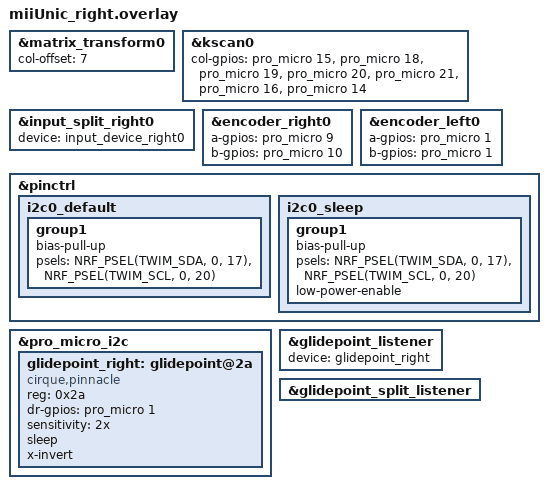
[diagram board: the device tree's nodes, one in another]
#include "miiUnic.dtsi"

&matrix_transform0 {
    col-offset = <7>;
};

&kscan0 {
    col-gpios
        = <&pro_micro 15 GPIO_ACTIVE_HIGH>
        , <&pro_micro 18 GPIO_ACTIVE_HIGH>
        , <&pro_micro 19 GPIO_ACTIVE_HIGH>
        , <&pro_micro 20 GPIO_ACTIVE_HIGH>
        , <&pro_micro 21 GPIO_ACTIVE_HIGH>
        , <&pro_micro 16 GPIO_ACTIVE_HIGH>
        , <&pro_micro 14 GPIO_ACTIVE_HIGH>
        ;
};
// == Input devices ==
// Enabling input-split for its own input devices
// Adding input devices and assigning them to input-split
&input_split_right0 {
    status = "okay";
    device = <&input_device_right0>;
};

&encoder_right0 {
    a-gpios = <&pro_micro 9 (GPIO_ACTIVE_HIGH | GPIO_PULL_UP)>;
    b-gpios = <&pro_micro 10 (GPIO_ACTIVE_HIGH | GPIO_PULL_UP)>;
    status = "okay";
};

// Assigning dummy pins to other part's encoders
// just to satisfy the devicetree requirements.
// No code will be compiled for these disabled encoders.
&encoder_left0 {
    a-gpios = <&pro_micro 1 (GPIO_ACTIVE_HIGH | GPIO_PULL_UP)>;
    b-gpios = <&pro_micro 1 (GPIO_ACTIVE_HIGH | GPIO_PULL_UP)>;
};

&pinctrl {
    /* configuration for i2c0 device, default state */
    i2c0_default: i2c0_default {
        group1 {
            bias-pull-up;
            psels = <NRF_PSEL(TWIM_SDA, 0, 17)>,
                    <NRF_PSEL(TWIM_SCL, 0, 20)>;
        };
    };
    /* configuration for i2c0 device, sleep state */
    i2c0_sleep: i2c0_sleep {
        group1 {
            bias-pull-up;
            psels = <NRF_PSEL(TWIM_SDA, 0, 17)>,
                    <NRF_PSEL(TWIM_SCL, 0, 20)>;
            low-power-enable;
        };
    };
};
&pro_micro_i2c {
    status = "okay";

    glidepoint_right: glidepoint@2a {
        compatible = "cirque,pinnacle";
        reg = <0x2a>;
        status = "okay";
        dr-gpios = <&pro_micro 1 (GPIO_ACTIVE_HIGH)>;
        sensitivity = "2x";
        sleep;
        //no-taps;
        //y-invert;
        x-invert;
    };
};

&glidepoint_listener {
    status = "okay";
    device = <&glidepoint_right>;
};

&glidepoint_split_listener {
    status = "okay";
};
